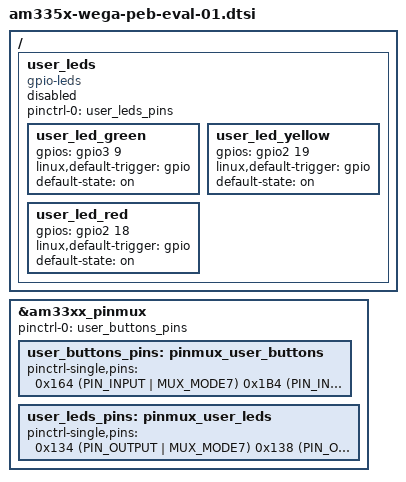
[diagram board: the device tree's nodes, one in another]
/* Copyright (C) 2014 Christian Arlt <c.arlt@phytec.de> Phytec Messtechnik GmbH
 *
 * This program is free software; you can redistribute it and/or modify
 * it under the terms of the GNU General Public License version 2 as
 * published by the Free Software Foundation.
 */

&am33xx_pinmux {
	pinctrl-names = "default";
	pinctrl-0 = <&user_buttons_pins>;

	user_buttons_pins: pinmux_user_buttons {
		pinctrl-single,pins = <
			0x164 (PIN_INPUT | MUX_MODE7)	/* ecap0_in_pwm0_out.gpio0_7	*/
			0x1B4 (PIN_INPUT | MUX_MODE7)	/* xdma_event_intr1.gpio0_20	*/
			0x130 (PIN_INPUT | MUX_MODE7)	/* mii1_rx_clk.gpio3_10		*/
		>;
	};

	user_leds_pins: pinmux_user_leds {
		pinctrl-single,pins = <
			0x134 (PIN_OUTPUT | MUX_MODE7)	/* mii1_rxd3.gpio2_18	*/
			0x138 (PIN_OUTPUT | MUX_MODE7)	/* mii1_rxd2.gpio2_19	*/
			0x12C (PIN_OUTPUT | MUX_MODE7)	/* mii1_tx_clk.gpio3_9	*/
		>;
	};
};

/ {
	user_leds: user_leds {
		compatible = "gpio-leds";
		pinctrl-names = "default";
		pinctrl-0 = <&user_leds_pins>;
		status = "disabled";

		user_led_green {
			gpios = <&gpio3 9 GPIO_ACTIVE_HIGH>;
			linux,default-trigger = "gpio";
			default-state = "on";
		};

		user_led_yellow {
			gpios = <&gpio2 19 GPIO_ACTIVE_HIGH>;
			linux,default-trigger = "gpio";
			default-state = "on";
		};

		user_led_red {
			gpios = <&gpio2 18 GPIO_ACTIVE_HIGH>;
			linux,default-trigger = "gpio";
			default-state = "on";
		};
	};
};
